# MINI58DE_v1 register map
File version: 1.0
Registers are 32-bit, read-write, reset 0x0 unless marked. A register's access mark holds for its fields unless they carry their own. Offsets are from the block's base; [hi:lo] are bit positions; {n}, {i} and the like mark numbered series.

## UART0 — UART Register Map
Base 0x40050000
0x00 UART_DAT reset not defined — UART Receive/Transmit Buffer Register
  [7:0] DAT — Receiving/Transmit Buffer. Write Operation: By writing one byte to this register, the data byte will be stored in transmitter FIFO. The UART Controller will send out the data stored in transmitter FIFO top location through the UART_TXD. Read Operation: By reading this register, the UART will return an 8-bit data received from receiving FIFO.
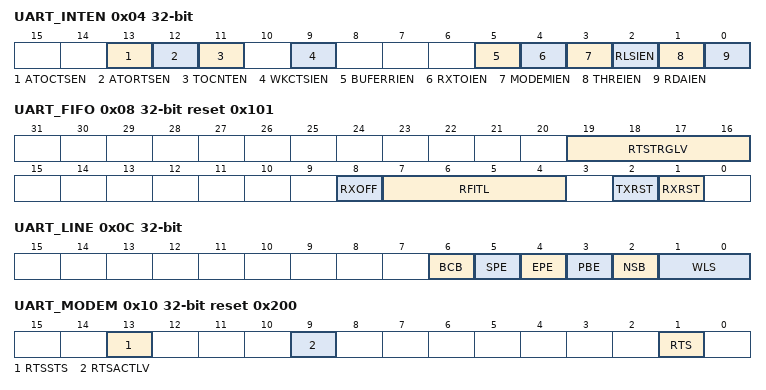
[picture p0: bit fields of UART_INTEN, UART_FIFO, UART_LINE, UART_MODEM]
0x04 UART_INTEN — UART Interrupt Enable Register
  [13] ATOCTSEN — CTS Auto Flow Control Enable Bit (Only Available In UART0). Note: When CTS auto-flow is enabled, the UART will send data to external device when CTS input assert (UART will not send data to device until CTS is asserted).
    0=CTS auto flow control Disabled; 1=CTS auto flow control Enabled
  [12] ATORTSEN — RTS Auto Flow Control Enable Bit (Only Available In UART0). Note: When RTS auto-flow is enabled, if the number of bytes in the RX FIFO equals the RTSTRGLV (UART_FIFO [19:16]), the UART will de-assert RTS signal.
    0=RTS auto flow control Disabled; 1=RTS auto flow control Enabled
  [11] TOCNTEN — Time-out Counter Enable Bit
    0=Time-out counter Disabled; 1=Time-out counter Enabled
  [9] WKCTSIEN — Wake-up CPU Function Interrupt Enable Bit (Only Available In UART0). Note: When the chip is in Power-down mode, an external CTS change will wake-up chip from Power-down mode.
    0=UART wake-up function Disabled; 1=UART Wake-up function Enabled
  [5] BUFERRIEN — Buffer Error Interrupt Enable Bit
    0=Buffer Error Interrupt Masked Disabled; 1=Buffer Error Interrupt Masked Enabled
  [4] RXTOIEN — RX Time-out Interrupt Enable Bit
    0=RXTOINT Masked off; 1=RXTOINT Enabled
  [3] MODEMIEN — Modem Status Interrupt Enable Bit
    0=MODEMINT Masked off; 1=MODEMINT Enabled
  [2] RLSIEN — Receive Line Status Interrupt Enable Bit
    0=RLSINT Masked off; 1=RLSINT Enabled
  [1] THREIEN — Transmit Holding Register Empty Interrupt Enable Bit
    0=THREINT Masked off; 1=THREINT Enabled
  [0] RDAIEN — Receive Data Available Interrupt Enable Bit
    0=RDAINT Masked off; 1=RDAINT Enabled
0x08 UART_FIFO reset 0x101 — UART FIFO Control Register
  [19:16] RTSTRGLV — RTS Trigger Level (For Auto-flow Control Use) (Only Available In UART0). Note: This field is used for RTS auto-flow control.
    0=RTS Trigger Level is 1 byte; 1=RTS Trigger Level is 4 bytes; 2=RTS Trigger Level is 8 bytes; 3=RTS Trigger Level is 14 bytes
  [8] RXOFF — Receiver Disable Register (Only Available In UART0). The receiver is disabled or not (setting 1 to disable the receiver). Note: This field is used for RS-485 Normal Multi-drop mode. It should be programmed before RS-485_NMM (UART_ALTCTL [8]) is programmed.
    0=Receiver Enabled; 1=Receiver Disabled
  [7:4] RFITL — RX FIFO Interrupt (RDAINT) Trigger Level (Only Available In UART0). When the number of bytes in the receive FIFO equals the RFITL then the RDAIF will be set (if RDAIEN in UART_INTEN register is enable, an interrupt will generated).
    0=RX FIFO Interrupt Trigger Level is 1 byte; 1=RX FIFO Interrupt Trigger Level is 4 bytes; 2=RX FIFO Interrupt Trigger Level is 8 bytes; 3=RX FIFO Interrupt Trigger Level is 14 bytes
  [2] TXRST — TX Field Software Reset. When TX_RST is set, all the byte in the transmit FIFO and TX internal state machine are cleared. Note: This bit will auto clear needs at least 3 UART Controller peripheral clock cycles.
    0=No effect; 1=Reset TX internal state machine and pointers reset
  [1] RXRST — RX Field Software Reset. When RX_RST is set, all the byte in the receiver FIFO and RX internal state machine are cleared. Note: This bit will auto clear needs at least 3 UART Controller peripheral clock cycles.
    0=No effect; 1=Reset RX internal state machine and pointers reset
0x0C UART_LINE — UART Line Control Register
  [6] BCB — Break Control Bit. When this bit is set to logic 1, the serial data output (TX) is forced to the Spacing State (logic 0). This bit acts only on TX and has no effect on the transmitter logic.
    0=Break control Disabled; 1=Break control Enabled
  [5] SPE — Stick Parity Enable Bit
    0=Stick parity Disabled; 1=If PBE (UART_LINE[3]) and EPE (UART_LINE[4]) are logic 1, the parity bit is transmitted and checked as logic 0. If PBE (UART_LINE[3]) is 1 and EPE (UART_LINE[4]) is 0 then the parity bit is transmitted and checked as 1
  [4] EPE — Even Parity Enable Bit. This bit has effect only when PBE (UART_LINE[3]) is set.
    0=Odd number of logic 1's is transmitted and checked in each word; 1=Even number of logic 1's is transmitted and checked in each word
  [3] PBE — Parity Bit Enable Bit
    0=No parity bit; 1=Parity bit is generated on each outgoing character and is checked on each incoming data
  [2] NSB — Number of "STOP Bit"
    0=One "STOP bit" is generated in the transmitted data; 1=When select 5-bit word length, 1.5 "STOP bit" is generated in the transmitted data. When select 6-, 7- and 8-bti word length, 2 "STOP bit" is generated in the transmitted data
  [1:0] WLS — Word Length Select Bit
    {v}=Word length is {v+5}-bit (v=0..3)
0x10 UART_MODEM reset 0x200 — UART Modem Control Register
  [13] RTSSTS ro — RTS Pin State (Read Only). This bit mirror from RTS pin output of voltage logic status.
    0=RTS pin output is low level voltage logic state; 1=RTS pin output is high level voltage logic state
  [9] RTSACTLV — RTS Pin Active Level. This bit defines the active level state of RTS pin output. Note1: Refer to Figure 6.1013 and Figure 6.1014 UART function mode. Note2: Refer to Figure 6.1017 and Figure 6.1018 for RS-485 function mode.
    0=RTS pin output is high level active; 1=RTS pin output is low level active. (Default)
  [1] RTS — RTS (Request-to-send) Signal Control. This bit is direct control internal RTS signal active or not, and then drive the RTS pin output with RTSACTLV bit configuration. Note1: This RTS signal control bit is not effective when RTS auto-flow control is enabled in UART function mode. Note2: This RTS signal control bit is not effective when RS-485 auto direction mode (AUD) is enabled in RS-485 function mode.
    0=RTS signal is active; 1=RTS signal is inactive
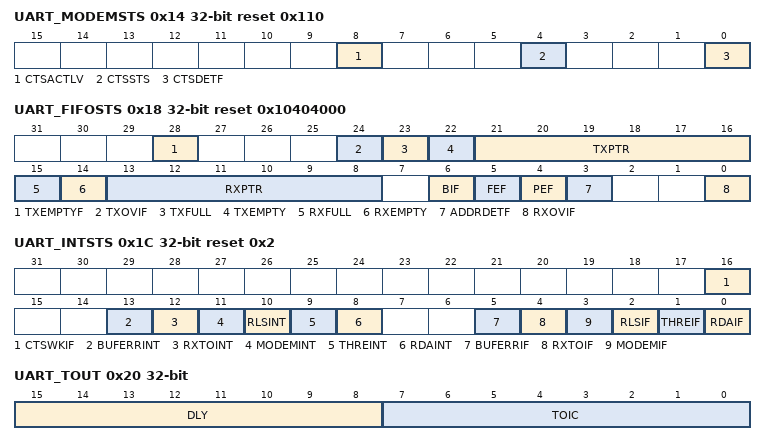
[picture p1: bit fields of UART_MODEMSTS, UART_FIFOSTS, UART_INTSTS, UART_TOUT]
0x14 UART_MODEMSTS reset 0x110 — UART Modem Status Register
  [8] CTSACTLV — CTS Pin Active Level. This bit defines the active level state of CTS pin input.
    0=CTS pin input is high level active; 1=CTS pin input is low level active. (Default)
  [4] CTSSTS ro — CTS Pin Status (Read Only). This bit mirror from CTS pin input of voltage logic status. Note: This bit echoes when UART Controller peripheral clock is enabled, and CTS multi-function port is selected.
    0=CTS pin input is low level voltage logic state; 1=CTS pin input is high level voltage logic state
  [0] CTSDETF — Detect CTS State Change Flag. This bit is set whenever CTS input has change state, and it will generate Modem interrupt to CPU when MODEMIEN (UART_INTEN [3]) is set to 1. Note: This bit is cleared by writing 1 to it.
    0=CTS input has not change state; 1=CTS input has change state
0x18 UART_FIFOSTS reset 0x10404000 — UART FIFO Status Register
  [28] TXEMPTYF ro — Transmitter Empty Flag (Read Only). This bit is set by hardware when TX FIFO (UART_DAT) is empty and the STOP bit of the last byte has been transmitted. Note: This bit is cleared automatically when TX FIFO is not empty or the last byte transmission has not completed.
    0=TX FIFO is not empty; 1=TX FIFO is empty
  [24] TXOVIF — TX Overflow Error Interrupt Flag. If TX FIFO (UART_DAT) is full, an additional write to UART_DAT will cause this bit to logic 1. Note: This bit is cleared by writing 1 to it.
    0=TX FIFO did not overflow; 1=TX FIFO overflowed
  [23] TXFULL ro — Transmitter FIFO Full (Read Only). This bit indicates TX FIFO full or not. Note: This bit is set when the number of usage in TX FIFO Buffer is equal to 16, otherwise is cleared by hardware.
    0=TX FIFO is not full; 1=TX FIFO is full
  [22] TXEMPTY ro — Transmitter FIFO Empty (Read Only). This bit indicates TX FIFO empty or not. Note: When the last byte of TX FIFO has been transferred to Transmitter Shift Register, hardware sets this bit high. It will be cleared when writing data into THR (TX FIFO not empty).
    0=TX FIFO is not empty; 1=TX FIFO is empty
  [21:16] TXPTR ro — TX FIFO Pointer (Read Only). This field indicates the TX FIFO Buffer Pointer. When CPU writes one byte into UART_DAT, TXPTR increases one. When one byte of TX FIFO is transferred to Transmitter Shift Register, TXPTR decreases one. The Maximum value shown in TXPTR is 15. When the using level of TX FIFO Buffer equal to 16, the TXFULL bit is set to 1 and TXPTR will show 0. As one byte of TX FIFO is transferred to Transmitter Shift Register, the TXFULL bit is cleared to 0 and TXPTR will show 15.
  [15] RXFULL ro — Receiver FIFO Full (Read Only). This bit initiates RX FIFO full or not. Note: This bit is set when the number of usage in RX FIFO Buffer is equal to 16, otherwise is cleared by hardware.
    0=RX FIFO is not full; 1=RX FIFO is full
  [14] RXEMPTY ro — Receiver FIFO Empty (Read Only). This bit initiate RX FIFO empty or not. Note: When the last byte of RX FIFO has been read by CPU, hardware sets this bit high. It will be cleared when UART receives any new data.
    0=RX FIFO is not empty; 1=RX FIFO is empty
  [13:8] RXPTR ro — RX FIFO Pointer (Read Only). This field indicates the RX FIFO Buffer Pointer. When UART receives one byte from external device, RXPTR increases one. When one byte of RX FIFO is read by CPU, RXPTR decreases one. The Maximum value shown in RXPTR is 15. When the using level of RX FIFO Buffer equal to 16, the RXFULL bit is set to 1 and RXPTR will show 0. As one byte of RX FIFO is read by CPU, the RXFULL bit is cleared to 0 and RXPTR will show 15.
  [6] BIF ro — Break Interrupt Flag (Read Only). This bit is set to logic 1 whenever the received data input (RX) is held in the "spacing state" (logic 0) for longer than a full word transmission time (that is, the total time of "start bit" + data bits + parity + stop bits). Note: This bit is read only, but software can write 1 to clear it.
    0=No Break interrupt is generated; 1=Break interrupt is generated
  [5] FEF ro — Framing Error Flag (Read Only). This bit is set to logic 1 whenever the received character does not have a valid "stop bit" (that is, the stop bit follows the last data bit or parity bit is detected as logic 0). Note: This bit is read only, but can be cleared by writing '1' to it .
    0=No framing error is generated; 1=Framing error is generated
  [4] PEF ro — Parity Error Flag (Read Only). This bit is set to logic 1 whenever the received character does not have a valid "parity bit". Note: This bit is read only, but can be cleared by writing '1' to it.
    0=No parity error is generated; 1=Parity error is generated
  [3] ADDRDETF — RS-485 Address Byte Detection Flag (Only Available In UART0). Note1: This field is used for RS-485 function mode. Note2: This bit is cleared by writing 1 to it.
  [0] RXOVIF — RX Overflow Error Interrupt Flag. This bit is set when RX FIFO overflow. If the number of bytes of received data is greater than RX_FIFO (UART_DAT) size, 16 bytes this bit will be set. Note: This bit is cleared by writing 1 to it.
    0=RX FIFO did not overflow; 1=RX FIFO overflowed
0x1C UART_INTSTS reset 0x2 — UART Interrupt Status Register
  [16] CTSWKIF ro — NCTS Wake-up Interrupt Flag (Read Only) (Only Available In UART0). Note1: If WKCTSIEN (UART_IER[9])is enabled, the wake-up interrupt is generated. Note2: This bit is read only, but can be cleared by writing '1' to it.
    0=Chip stays in power-down state; 1=Chip wake-up from power-down state by nCTS wake-up
  [13] BUFERRINT ro — Buffer Error Interrupt Indicator (Read Only). This bit is set if BUFERRIEN (UART_INTEN[5]) and BUFERRIF (UART_INTSTS[5]) are both set to 1.
    0=No buffer error interrupt is generated; 1=buffer error interrupt is generated
  [12] RXTOINT ro — Time-out Interrupt Indicator (Read Only). This bit is set if RXTOIEN (UART_INTEN[4]) and RXTOIF (UART_INTSTS[4]) are both set to 1.
    0=No Time-out interrupt is generated; 1=Time-out interrupt is generated
  [11] MODEMINT ro — MODEM Status Interrupt Indicator (Read Only). This bit is set if MODEMIEN (UART_INTEN[3]) and MODENIF (UART_INTSTS[3]) are both set to 1.
    0=No Modem interrupt is generated; 1=Modem interrupt is generated
  [10] RLSINT ro — Receive Line Status Interrupt (Read Only). This bit is set if RLSIEN (UART_INTEN[2]) and RLSIF (UART_INTSTS[2]) are both set to 1.
    0=No RLS interrupt is generated; 1=RLS interrupt is generated
  [9] THREINT ro — Transmit Holding Register Empty Interrupt Indicator (Read Only). This bit is set if THREIEN (UART_INTEN[1]) and THREIF (UART_INTSTS[1]) are both set to 1.
    0=No THRE interrupt is generated; 1=THRE interrupt is generated
  [8] RDAINT ro — Receive Data Available Interrupt Indicator (Read Only). This bit is set if RDAIEN (UART_INTEN[0]) and RDAIF (UART_INTSTS[0]) are both set to 1.
    0=No RDA interrupt is generated; 1=RDA interrupt is generated
  [5] BUFERRIF ro — Buffer Error Interrupt Flag (Read Only). This bit is set when the TX/RX FIFO overflow flag (TXOVIF (UART_FIFOSTS[24] or RXOVIF(UART_FIFOSTS[0])) is set. When BUFERRIF (UART_INTSTS[5]) is set, the transfer is not correct. If BUFERRIEN (UART_INTEN[5]) is enabled, the buffer error interrupt will be generated. Note: This bit is read only and reset to 0 when all bits of TXOVIF (UART_FIFOSTS[24]) and RXOVIF (UART_FIFOSTS[0]) are cleared.
    0=No buffer error interrupt flag is generated; 1=Buffer error interrupt flag is generated
  [4] RXTOIF ro — Time-out Interrupt Flag (Read Only). This bit is set when the RX FIFO is not empty and no activities occurred in the RX FIFO and the time-out counter equal to TOIC (UARTTOUT[7:0]). If RXTOIEN (UART_INTEN [4]) is enabled, the Tout interrupt will be generated. Note: This bit is read only and user can read UART_DAT (RX is in active) to clear it.
    0=No Time-out interrupt flag is generated; 1=Time-out interrupt flag is generated
  [3] MODEMIF ro — MODEM Interrupt Flag (Read Only) (Only Available In UART0). Note: This bit is read only and reset to 0 when bit CTSDETF (UART_MODEMSTS[0]) is cleared by a write 1 on CTSDETF (UART_MODEMSTS[0]).
    0=No Modem interrupt flag is generated; 1=Modem interrupt flag is generated
  [2] RLSIF ro — Receive Line Interrupt Flag (Read Only). This bit is set when the RX receive data have parity error, framing error or break error (at least one of 3 bits, BIF, FEF and PEF, is set). If RLSIEN (UART_INTEN [2]) is enabled, the RLS interrupt will be generated. Note2: This bit is read only and reset to 0 when all bits of BIF (UART_FIFOSTS[6]), FEF (UART_FIFOSTS[5]), PEF (UART_FIFOSTS[4]) and ADDRDETF (UART_FIFOSTS[3]) are cleared. (Only Available in UART0)
    0=No RLS interrupt flag is generated; 1=RLS interrupt flag is generated
  [1] THREIF ro — Transmit Holding Register Empty Interrupt Flag (Read Only). This bit is set when the last data of TX FIFO is transferred to Transmitter Shift Register. If THREIEN (UART_INTEN [1]) is enabled, the THRE interrupt will be generated. Note: This bit is read only and it will be cleared when writing data into UART_DAT (TX FIFO not empty).
    0=No THRE interrupt flag is generated; 1=THRE interrupt flag is generated
  [0] RDAIF ro — Receive Data Available Interrupt Flag (Read Only). When the number of bytes in the RX FIFO equals the RFITL(UART_FIFO[7:4]) then the RDAIF(UART_INTSTS[0]) will be set. If RDAIEN (UART_INTEN [0]) is enabled, the RDA interrupt will be generated. Note: This bit is read only and it will be cleared when the number of unread bytes of RX FIFO drops below the threshold level (RFITL (UART_FIFO[7:4])).
    0=No RDA interrupt flag is generated; 1=RDA interrupt flag is generated
0x20 UART_TOUT — UART Time-out Register
  [15:8] DLY — TX Delay Time Value. This field is used to program the transfer delay time between the last stop bit and next start bit. The Unit is bit time.
  [7:0] TOIC — Time-out Interrupt Comparator
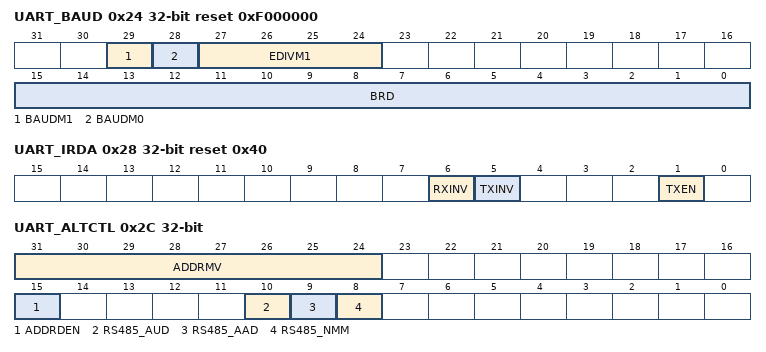
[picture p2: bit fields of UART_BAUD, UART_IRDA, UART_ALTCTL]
0x24 UART_BAUD reset 0xF000000 — UART Baud Rate Divisor Register
  [29] BAUDM1 — Divider X Enable Bit. Note: In IrDA mode, this bit must be disabled.
    0=Divider X Disabled (the equation of M = 16); 1=Divider X Enabled (the equation of M = X+1, but EDIVM1 [27:24] must = 8)
  [28] BAUDM0 — Divider X Equal 1. Note: Refer to section "UART Controller Baud Rate Generator" for more information.
    0=Divider M = X (the equation of M = X+1, but EDIVM1[27:24] must = 8); 1=Divider M = 1 (the equation of M = 1, but BRD [15:0] must = 8)
  [27:24] EDIVM1 — Divider X
  [15:0] BRD — Baud Rate Divider. The field indicates the baud rate divider.
0x28 UART_IRDA reset 0x40 — UART IrDA Control Register
  [6] RXINV — IrDA Inverse Receive Input Signal
    0=None inverse receiving input signal; 1=Inverse receiving input signal. (Default)
  [5] TXINV — IrDA Inverse Transmitting Output Signal
    0=None inverse transmitting signal. (Default); 1=Inverse transmitting output signal
  [1] TXEN — IrDA Receiver/Transmitter Selection Enable Bit
    0=IrDA Transmitter Disabled and Receiver Enabled. (Default); 1=IrDA Transmitter Enabled and Receiver Disabled
0x2C UART_ALTCTL — UART Alternate Control/Status Register
  [31:24] ADDRMV — Address Match Values. This field contains the RS-485 address match values. Note: This field is used for RS-485 auto address detection mode.
  [15] ADDRDEN — RS-485 Address Detection Enable Bit. This bit is used to enable RS-485 Address Detection mode. Note: This field is used for RS-485 any operation mode.
    0=RS-485 address detection mode Disabled; 1=RS-485 address detection mode Enabled
  [10] RS485_AUD — RS-485 Auto Direction Mode (AUD) Control. Note: It cannot be active with RS485_NMM operation mode.
    0=RS-485 Auto Direction Function Mode (AUD) Disabled; 1=RS-485 Auto Direction Function Mode (AUD) Enabled
  [9] RS485_AAD — RS-485 Auto Address Detection Operation Mode (AAD). Note: It cannot be active with RS485_NMM operation mode.
    0=RS-485 Auto Address Detection Operation Mode (AAD) Disabled; 1=RS-485 Auto Address Detection Operation Mode (AAD) Enabled
  [8] RS485_NMM — RS-485 Normal Multi-drop Operation Mode (NMM) Control. Note: It cannot be active with RS485_AAD operation mode.
    0=RS-485 Normal Multi-drop Operation Mode (NMM) Disabled; 1=RS-485 Normal Multi-drop Operation Mode (NMM) Enabled
0x30 UART_FUNSEL — UART Function Select Register
  [1:0] FUN_SEL — Function Selection
    0=UART function mode; 2=IrDA function mode. (Only Available in UART0); 3=RS-485 function mode. (Only Available in UART0)
